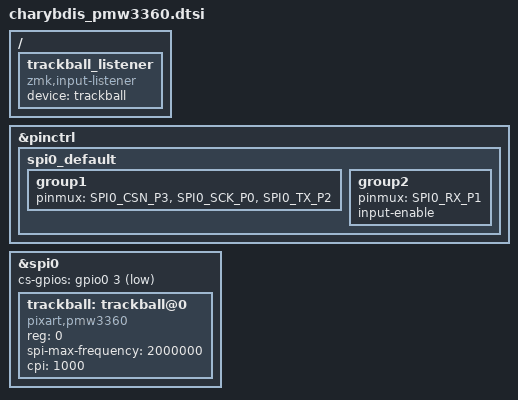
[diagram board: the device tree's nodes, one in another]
&pinctrl {
    spi0_default: spi0_default {
        group1 {
            pinmux = <SPI0_CSN_P3>, <SPI0_SCK_P0>, <SPI0_TX_P2>;
        };
        group2 {
            pinmux = <SPI0_RX_P1>;
            input-enable;
        };
    };
};

&spi0 {
    status = "okay";
    cs-gpios = <&gpio0 3 GPIO_ACTIVE_LOW>;

    trackball: trackball@0 {
        compatible = "pixart,pmw3360";
        status = "okay";
        reg = <0>;
        spi-max-frequency = <2000000>;
        cpi = <1000>;
    };
};

/ {
    trackball_listener {
        compatible = "zmk,input-listener";
        device = <&trackball>;
    };
};
